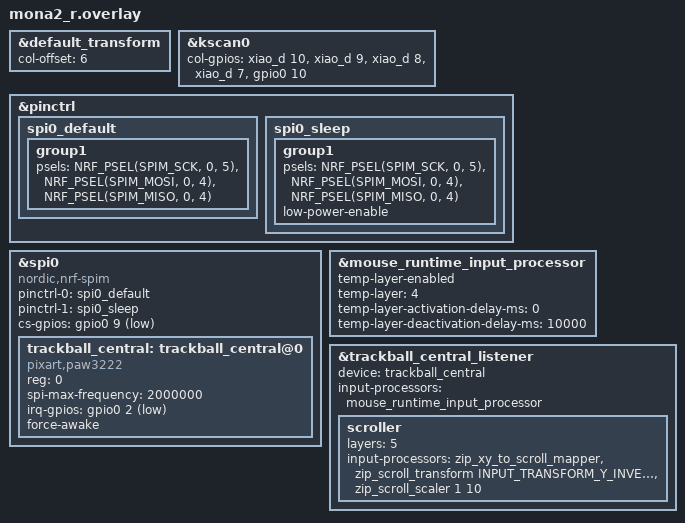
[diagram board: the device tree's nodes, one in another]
#include "mona2.dtsi"

/* mona2.dtsi 内で RC(row,col) のマトリクス展開が終わった後に include する
   (runtime-input-processor.dtsi が modifiers.h 経由で RC(keycode) を再定義するため) */
#include <input/processors/runtime-input-processor.dtsi>
#include <input/processors.dtsi>
#include <zephyr/dt-bindings/input/input-event-codes.h>

&default_transform {
    col-offset = <6>;
};

&kscan0 {
        col-gpios
            = <&xiao_d 10 GPIO_ACTIVE_HIGH>
            , <&xiao_d 9 GPIO_ACTIVE_HIGH>
            , <&xiao_d 8 GPIO_ACTIVE_HIGH>
            , <&xiao_d 7 GPIO_ACTIVE_HIGH>
            , <&gpio0 10 GPIO_ACTIVE_HIGH>
            ;
};


&pinctrl {
    spi0_default: spi0_default {    //通常時(SPI通信中)のピン構成
        group1 {
            psels = <NRF_PSEL(SPIM_SCK, 0, 5)>, //P0.05を指定(SCLK)
                <NRF_PSEL(SPIM_MOSI, 0, 4)>,    //P0.04を指定(SDIOだからMOSI,MISO両方の役割を担う)
                <NRF_PSEL(SPIM_MISO, 0, 4)>;
        };
    };

    spi0_sleep: spi0_sleep {    //スリープ時のピン構成(省電力)
        group1 {
            psels = <NRF_PSEL(SPIM_SCK, 0, 5)>,
                <NRF_PSEL(SPIM_MOSI, 0, 4)>,
                <NRF_PSEL(SPIM_MISO, 0, 4)>;
            low-power-enable;
        };
    };
};


&spi0 {
    status = "okay";
    compatible = "nordic,nrf-spim"; //マイコンがnRFシリーズ
    pinctrl-0 = <&spi0_default>;
    pinctrl-1 = <&spi0_sleep>;
    pinctrl-names = "default", "sleep";
    cs-gpios = <&gpio0 9 GPIO_ACTIVE_LOW>;  //P0.09を指定(CS)

    trackball_central: trackball_central@0 {
        status = "okay";
        compatible = "pixart,paw3222";  //トラボセンサ用のドライバとバインド
        reg = <0>;
        spi-max-frequency = <2000000>;
        irq-gpios = <&gpio0 2 (GPIO_ACTIVE_LOW | GPIO_PULL_UP)>; //P0.02を指定(MOTION)
        force-awake;
    };
};


/* ─────────────────────────────────────────────────────────────
   mouse_runtime_input_processor
   ・通常時のマウス移動 + オートマウスレイヤー
   ・元の &zip_temp_layer 4 10000 相当
   ────────────────────────────────────────────────────── */
&mouse_runtime_input_processor {
    temp-layer-enabled;
    temp-layer = <4>;                          /* MOUSE レイヤー */
    temp-layer-activation-delay-ms = <0>;
    temp-layer-deactivation-delay-ms = <10000>;
};

/* ─────────────────────────────────────────────────────────────
   入力リスナー
   ・メインチェーン: 通常時はマウス移動 + オートマウスレイヤー
   ・scroller 子ノード: layer 5 (SCROLL) のときだけスクロール変換
     （元の設定と同じ方式。active-layers より確実）
   ────────────────────────────────────────────────────── */
&trackball_central_listener {
    status = "okay";
    device = <&trackball_central>;

    /* 通常時（SCROLL 以外） */
    input-processors = <&mouse_runtime_input_processor>;

    /* SCROLL レイヤー (layer 5) のときだけこちらに切替 */
    scroller {
        layers = <5>;
        input-processors =
            <&zip_xy_to_scroll_mapper>,
            <&zip_scroll_transform INPUT_TRANSFORM_Y_INVERT>,
            <&zip_scroll_scaler 1 10>;
    };
};
